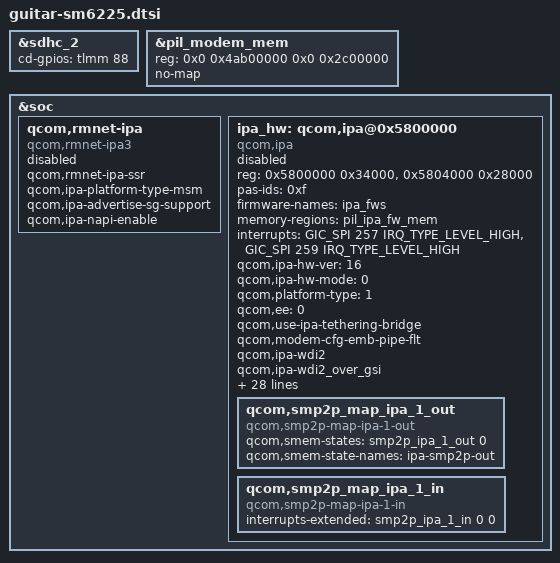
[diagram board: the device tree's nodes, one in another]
/*
  this file is for attribution only of zeus
  And public attribution of longcheer platforms(like M7 and so and)
*/
#include "longcheer-sm6225-common.dtsi"
#include "guitar-pinctrl.dtsi"
#include "lc_chg/lc_chg.dtsi"
#include <dt-bindings/clock/qcom,rpmcc.h>
#include <dt-bindings/interconnect/qcom,bengal.h>

&sdhc_2 {
	cd-gpios = <&tlmm 88 GPIO_ACTIVE_HIGH>;
};

&pil_modem_mem {
			reg = <0x0 0x4ab00000 0x0 0x2c00000>;
                        no-map;
		};

&soc {
	qcom,rmnet-ipa {
		compatible = "qcom,rmnet-ipa3";
		qcom,rmnet-ipa-ssr;
		qcom,ipa-platform-type-msm;
		qcom,ipa-advertise-sg-support;
		qcom,ipa-napi-enable;
		status = "disabled";
	};

	ipa_hw: qcom,ipa@0x5800000 {
		compatible = "qcom,ipa";
		reg = <0x5800000 0x34000>,
			<0x5804000 0x28000>;
		status = "disabled";
		pas-ids = <0xf>;
		firmware-names = "ipa_fws";
		memory-regions = <&pil_ipa_fw_mem>;
		reg-names = "ipa-base", "gsi-base";
		interrupts = <GIC_SPI 257 IRQ_TYPE_LEVEL_HIGH>,
				<GIC_SPI 259 IRQ_TYPE_LEVEL_HIGH>;
		interrupt-names = "ipa-irq", "gsi-irq";
		qcom,ipa-hw-ver = <16>; /* IPA core version = IPAv4.2 */
		qcom,ipa-hw-mode = <0>;
		qcom,platform-type = <1>; /* MSM platform */
		qcom,ee = <0>;
		qcom,use-ipa-tethering-bridge;
		qcom,modem-cfg-emb-pipe-flt;
		qcom,ipa-wdi2;
		qcom,ipa-wdi2_over_gsi;
		qcom,ipa-endp-delay-wa;
		qcom,ipa-fltrt-not-hashable;
		qcom,use-64-bit-dma-mask;
		qcom,arm-smmu;
		qcom,smmu-fast-map;
		qcom,use-ipa-pm;
		qcom,skip-ieob-mask-wa;
		qcom,max_num_smmu_cb = <3>;
		clocks = <&rpmcc RPM_SMD_IPA_CLK>;
		clock-names = "core_clk";
		qcom,interconnect,num-cases = <5>;
		qcom,interconnect,num-paths = <3>;
		interconnects = <&system_noc MASTER_IPA &bimc SLAVE_EBI_CH0>,
			<&system_noc MASTER_IPA &system_noc SLAVE_OCIMEM>,
			<&bimc MASTER_AMPSS_M0 &config_noc SLAVE_IPA_CFG>;
		interconnect-names = "ipa_to_ebi1", "ipa_to_imem", "appss_to_ipa";
		/* No vote */
		qcom,no-vote =
		<0 0 0 0 0 0>;
		/* SVS2 */
		qcom,svs2 =
		<80000 465000 80000 68570 80000 30>;
		/* SVS */
		qcom,svs =
		<80000 2000000 80000 267461 80000 109890>;
		/* NOMINAL */
		qcom,nominal =
		<206000 4000000 206000 712961 206000 491520>;
		/* TURBO */
		qcom,turbo =
		<206000 5598900 206000 1436481 206000 491520>;

		qcom,bus-vector-names =
				"MIN", "SVS2", "SVS", "NOMINAL", "TURBO";
		qcom,throughput-threshold = <310 600 1000>;
		qcom,scaling-exceptions = <>;

		/* smp2p information */
		qcom,smp2p_map_ipa_1_out {
			compatible = "qcom,smp2p-map-ipa-1-out";
		qcom,smem-states = <&smp2p_ipa_1_out 0>;
			qcom,smem-state-names = "ipa-smp2p-out";
		};

		qcom,smp2p_map_ipa_1_in {
			compatible = "qcom,smp2p-map-ipa-1-in";
			interrupts-extended = <&smp2p_ipa_1_in 0 0>;
			interrupt-names = "ipa-smp2p-in";
		};
	};
};
